AUTOSAR XML (schema 00047)
package /ETAS_FlatView/SwComponentTypes
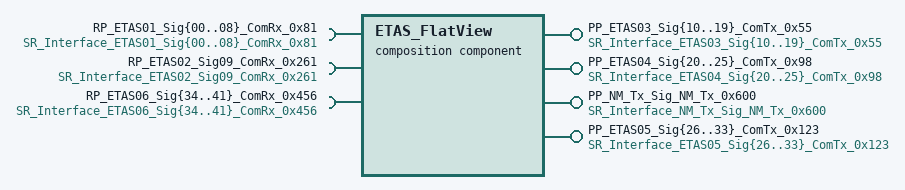
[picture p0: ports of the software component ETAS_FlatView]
  composition sw component type ETAS_FlatView
    17 x provide port:
      PP_ETAS03_Sig{10..19}_ComTx_0x55: provided-interface=SR_Interface_ETAS03_Sig{10..19}_ComTx_0x55
      PP_ETAS04_Sig{20..25}_ComTx_0x98: provided-interface=SR_Interface_ETAS04_Sig{20..25}_ComTx_0x98
      PP_NM_Tx_Sig_NM_Tx_0x600: provided-interface=SR_Interface_NM_Tx_Sig_NM_Tx_0x600
    10 x require port:
      RP_ETAS01_Sig{00..08}_ComRx_0x81: required-interface=SR_Interface_ETAS01_Sig{00..08}_ComRx_0x81
      RP_ETAS02_Sig09_ComRx_0x261: required-interface=SR_Interface_ETAS02_Sig09_ComRx_0x261
    8 x provide port:
      PP_ETAS05_Sig{26..33}_ComTx_0x123: provided-interface=SR_Interface_ETAS05_Sig{26..33}_ComTx_0x123
    8 x require port:
      RP_ETAS06_Sig{34..41}_ComRx_0x456: required-interface=SR_Interface_ETAS06_Sig{34..41}_ComRx_0x456
    23 x component:
      CPT_BswM: type=BswM
      CPT_CalUT: type=CalUT
      CPT_ComM: type=ComM
      CPT_Dcm: type=Dcm
      CPT_Dem: type=Dem
      CPT_Det: type=Det
      CPT_DiagUT: type=DiagUT
      CPT_EcuM: type=EcuM
      CPT_ExeMgrUT: type=ExeMgrUT
      CPT_FiM: type=FiM
      CPT_INP_SWC: type=INP_SWC
      CPT_NmUT: type=NmUT
      CPT_NvBlock: type=NvBlock
      CPT_NvM: type=NvM
      CPT_NvMUT: type=NvMUT
      CPT_OUTP_SWC: type=OUTP_SWC
      CPT_ParameterSWC: type=ParameterSWC
      CPT_Rtm: type=Rtm
      CPT_StackM: type=StackM
      CPT_TstM: type=TstM
      CPT_WdgM: type=WdgM
      CPT_WdgMUT: type=WdgMUT
      CPT_rba_DiagLib: type=rba_DiagLib
    connect CPT_ComM.UR_ComMUser_Can_Network_ETAS_Channel_Can_Network_ETAS -> CPT_NmUT.UR_ComMUser_Can_Network_ETAS_Channel
    connect CPT_ComM.modeLimitation -> CPT_NmUT.modeLimitation
    connect CPT_Dcm.DCMServices -> CPT_DiagUT.DCMServices
    connect CPT_Dcm.IOControlRequest_DID_0xD901_New_Data_Object -> CPT_DiagUT.IOControlRequest_DID_0xD901_New_Data_Object
    connect CPT_Dcm.IOControlRequest_DID_0xE900_New_Data_Object -> CPT_DiagUT.IOControlRequest_DID_0xE900_New_Data_Object
    connect CPT_Dcm.P_DataServices_DID_0x0100_New_Data_Object -> CPT_DiagUT.R_DataServices_DID_0x0100_New_Data_Object
    connect CPT_Dcm.P_DataServices_DID_0xF110_New_Data_Object -> CPT_DiagUT.R_DataServices_DID_0xF110_New_Data_Object
    connect CPT_Dcm.P_DataServices_DID_0xF115_New_Data_Object -> CPT_DiagUT.R_DataServices_DID_0xF115_New_Data_Object
    connect CPT_Dcm.P_DataServices_DID_0xF121_New_Data_Object -> CPT_DiagUT.R_DataServices_DID_0xF121_New_Data_Object
    connect CPT_Dcm.P_DataServices_DID_0xF187_New_Data_Object -> CPT_DiagUT.R_DataServices_DID_0xF187_New_Data_Object
    connect CPT_Dcm.P_DataServices_DID_0xF18B_New_Data_Object -> CPT_DiagUT.R_DataServices_DID_0xF18B_New_Data_Object
    connect CPT_Dcm.P_DataServices_DID_0xF18C_New_Data_Object -> CPT_DiagUT.R_DataServices_DID_0xF18C_New_Data_Object
    connect CPT_Dcm.P_DataServices_DID_0xF190_New_Data_Object -> CPT_DiagUT.R_DataServices_DID_0xF190_New_Data_Object
    connect CPT_Dcm.P_DataServices_DID_0xF198_New_Data_Object -> CPT_DiagUT.R_DataServices_DID_0xF198_New_Data_Object
    connect CPT_Dcm.P_DataServices_DID_0xF198_New_Data_Object_5 -> CPT_DiagUT.R_DataServices_DID_0xF198_New_Data_Object_5
    connect CPT_Dcm.P_DataServices_DID_0xF1A8_New_Data_Object -> CPT_DiagUT.R_DataServices_DID_0xF1A8_New_Data_Object
    connect CPT_Dcm.P_DataServices_DID_0xF1A9_New_Data_Object -> CPT_DiagUT.R_DataServices_DID_0xF1A9_New_Data_Object
    connect CPT_Dcm.P_DataServices_DID_0xF1AA_New_Data_Object -> CPT_DiagUT.R_DataServices_DID_0xF1AA_New_Data_Object
    connect CPT_Dcm.Pp_DcmCommunicationControl_Can_Network_ETAS_Channel_Can_Network_ETAS -> CPT_DiagUT.RR_DcmCommunicationControl_ComMChannel_Can_Network_ETAS_Channel
    connect CPT_Dcm.Pp_DcmControlDTCSetting -> CPT_DiagUT.RR_DcmControlDTCSetting
    connect CPT_Dcm.Pp_DcmDiagnosticSessionControl -> CPT_DiagUT.RR_DcmDiagnosticSessionControl
    connect CPT_Dcm.Pp_DcmEcuReset -> CPT_DiagUT.RR_DcmEcuReset
    connect CPT_Dem.ControlEventAvailable_DTC_0x000001_Event -> CPT_DiagUT.ControlEventAvailable_EventParameter_DTC_0x000001_Event
    connect CPT_Dem.ControlEventAvailable_DTC_0xc07388_Event -> CPT_DiagUT.ControlEventAvailable_EventParameter_DTC_0xc07388_Event
    connect CPT_Dem.ControlEventAvailable_DTC_0xc12687_Event -> CPT_DiagUT.ControlEventAvailable_EventParameter_DTC_0xc12687_Event
    connect CPT_Dem.ControlEventAvailable_DTC_0xc14587_Event -> CPT_DiagUT.ControlEventAvailable_EventParameter_DTC_0xc14587_Event
    connect CPT_Dem.ControlEventAvailable_DTC_0xc22a87_Event -> CPT_DiagUT.ControlEventAvailable_EventParameter_DTC_0xc22a87_Event
    connect CPT_Dem.ControlEventAvailable_DTC_0xc41487_Event -> CPT_DiagUT.ControlEventAvailable_EventParameter_DTC_0xc41487_Event
    connect CPT_Dem.ControlEventAvailable_DTC_0xd56217_Event -> CPT_DiagUT.ControlEventAvailable_EventParameter_DTC_0xd56217_Event
    connect CPT_Dem.ControlEventAvailable_DTC_0xd56316_Event -> CPT_DiagUT.ControlEventAvailable_EventParameter_DTC_0xd56316_Event
    connect CPT_Dem.ControlEventAvailable_DTC_0xe00141_Event -> CPT_DiagUT.ControlEventAvailable_EventParameter_DTC_0xe00141_Event
    connect CPT_Dem.ControlEventAvailable_DTC_0xe00142_Event -> CPT_DiagUT.ControlEventAvailable_EventParameter_DTC_0xe00142_Event
    connect CPT_Dem.ControlEventAvailable_DTC_0xe26200_Event -> CPT_DiagUT.ControlEventAvailable_EventParameter_DTC_0xe26200_Event
    connect CPT_Dem.EventStatus_DTC_0x000001_Event -> CPT_DiagUT.EventStatus_EventParameter_DTC_0x000001_Event
    connect CPT_Dem.EventStatus_DTC_0xc07388_Event -> CPT_DiagUT.EventStatus_EventParameter_DTC_0xc07388_Event
    connect CPT_Dem.EventStatus_DTC_0xc12687_Event -> CPT_DiagUT.EventStatus_EventParameter_DTC_0xc12687_Event
    connect CPT_Dem.EventStatus_DTC_0xc14587_Event -> CPT_DiagUT.EventStatus_EventParameter_DTC_0xc14587_Event
    connect CPT_Dem.EventStatus_DTC_0xc22a87_Event -> CPT_DiagUT.EventStatus_EventParameter_DTC_0xc22a87_Event
    connect CPT_Dem.EventStatus_DTC_0xc41487_Event -> CPT_DiagUT.EventStatus_EventParameter_DTC_0xc41487_Event
    connect CPT_Dem.EventStatus_DTC_0xd56217_Event -> CPT_DiagUT.EventStatus_EventParameter_DTC_0xd56217_Event
    connect CPT_Dem.EventStatus_DTC_0xd56316_Event -> CPT_DiagUT.EventStatus_EventParameter_DTC_0xd56316_Event
    connect CPT_Dem.EventStatus_DTC_0xe00141_Event -> CPT_DiagUT.EventStatus_EventParameter_DTC_0xe00141_Event
    connect CPT_Dem.EventStatus_DTC_0xe00142_Event -> CPT_DiagUT.EventStatus_EventParameter_DTC_0xe00142_Event
    connect CPT_Dem.EventStatus_DTC_0xe26200_Event -> CPT_DiagUT.EventStatus_EventParameter_DTC_0xe26200_Event
    connect CPT_Dem.Event_DTC_0x000001_Event -> CPT_DiagUT.Event_EventParameter_DTC_0x000001_Event
    connect CPT_Dem.Event_DTC_0xc07388_Event -> CPT_DiagUT.Event_EventParameter_DTC_0xc07388_Event
    connect CPT_Dem.Event_DTC_0xc12687_Event -> CPT_DiagUT.Event_EventParameter_DTC_0xc12687_Event
    connect CPT_Dem.Event_DTC_0xc14587_Event -> CPT_DiagUT.Event_EventParameter_DTC_0xc14587_Event
    connect CPT_Dem.Event_DTC_0xc22a87_Event -> CPT_DiagUT.Event_EventParameter_DTC_0xc22a87_Event
    connect CPT_Dem.Event_DTC_0xc41487_Event -> CPT_DiagUT.Event_EventParameter_DTC_0xc41487_Event
    connect CPT_Dem.Event_DTC_0xd56217_Event -> CPT_DiagUT.Event_EventParameter_DTC_0xd56217_Event
    connect CPT_Dem.Event_DTC_0xd56316_Event -> CPT_DiagUT.Event_EventParameter_DTC_0xd56316_Event
    connect CPT_Dem.Event_DTC_0xe00141_Event -> CPT_DiagUT.Event_EventParameter_DTC_0xe00141_Event
    connect CPT_Dem.Event_DTC_0xe00142_Event -> CPT_DiagUT.Event_EventParameter_DTC_0xe00142_Event
    connect CPT_Dem.Event_DTC_0xe26200_Event -> CPT_DiagUT.Event_EventParameter_DTC_0xe26200_Event
    connect CPT_Dem.EvtInfo_DTC_0x000001_Event -> CPT_DiagUT.EvtInfo_EventParameter_DTC_0x000001_Event
    connect CPT_Dem.EvtInfo_DTC_0x0d0400_CAN_Network_ETAS_BusOff_Event -> CPT_DiagUT.EvtInfo_EventParameter_DTC_0x0d0400_CAN_Network_ETAS_BusOff_Event
    connect CPT_Dem.EvtInfo_DTC_0xc07388_Event -> CPT_DiagUT.EvtInfo_EventParameter_DTC_0xc07388_Event
    connect CPT_Dem.EvtInfo_DTC_0xc12687_Event -> CPT_DiagUT.EvtInfo_EventParameter_DTC_0xc12687_Event
    connect CPT_Dem.EvtInfo_DTC_0xc14587_Event -> CPT_DiagUT.EvtInfo_EventParameter_DTC_0xc14587_Event
    connect CPT_Dem.EvtInfo_DTC_0xc22a87_Event -> CPT_DiagUT.EvtInfo_EventParameter_DTC_0xc22a87_Event
    connect CPT_Dem.EvtInfo_DTC_0xc41487_Event -> CPT_DiagUT.EvtInfo_EventParameter_DTC_0xc41487_Event
    connect CPT_Dem.EvtInfo_DTC_0xd56217_Event -> CPT_DiagUT.EvtInfo_EventParameter_DTC_0xd56217_Event
    connect CPT_Dem.EvtInfo_DTC_0xd56316_Event -> CPT_DiagUT.EvtInfo_EventParameter_DTC_0xd56316_Event
    connect CPT_Dem.EvtInfo_DTC_0xe00141_Event -> CPT_DiagUT.EvtInfo_EventParameter_DTC_0xe00141_Event
    connect CPT_Dem.EvtInfo_DTC_0xe00142_Event -> CPT_DiagUT.EvtInfo_EventParameter_DTC_0xe00142_Event
    connect CPT_Dem.EvtInfo_DTC_0xe26200_Event -> CPT_DiagUT.EvtInfo_EventParameter_DTC_0xe26200_Event
    connect CPT_Dem.GeneralEvtInfo -> CPT_DiagUT.GeneralEvtInfo
    connect CPT_Dem.OpCycle_DemOpCycle_DEM_POWER -> CPT_DiagUT.OpCycle_DemOpCycle_DEM_POWER
    connect CPT_Dem.StorageCond_DemStorageCondition -> CPT_DiagUT.StorageCond_DemStorageCondition_0
    connect CPT_DiagUT.CBClrEvt_EventParameter_DTC_0x000001_Event -> CPT_Dem.CBClrEvt_DTC_0x000001_Event
    connect CPT_DiagUT.CBClrEvt_EventParameter_DTC_0x0d0400_CAN_Network_ETAS_BusOff_Event -> CPT_Dem.CBClrEvt_DTC_0x0d0400_CAN_Network_ETAS_BusOff_Event
    connect CPT_DiagUT.CBClrEvt_EventParameter_DTC_0xc07388_Event -> CPT_Dem.CBClrEvt_DTC_0xc07388_Event
    connect CPT_DiagUT.CBClrEvt_EventParameter_DTC_0xc12687_Event -> CPT_Dem.CBClrEvt_DTC_0xc12687_Event
    connect CPT_DiagUT.CBClrEvt_EventParameter_DTC_0xc14587_Event -> CPT_Dem.CBClrEvt_DTC_0xc14587_Event
    connect CPT_DiagUT.CBClrEvt_EventParameter_DTC_0xc22a87_Event -> CPT_Dem.CBClrEvt_DTC_0xc22a87_Event
    connect CPT_DiagUT.CBClrEvt_EventParameter_DTC_0xc41487_Event -> CPT_Dem.CBClrEvt_DTC_0xc41487_Event
    connect CPT_DiagUT.CBClrEvt_EventParameter_DTC_0xd56217_Event -> CPT_Dem.CBClrEvt_DTC_0xd56217_Event
    connect CPT_DiagUT.CBClrEvt_EventParameter_DTC_0xd56316_Event -> CPT_Dem.CBClrEvt_DTC_0xd56316_Event
    connect CPT_DiagUT.CBClrEvt_EventParameter_DTC_0xe00141_Event -> CPT_Dem.CBClrEvt_DTC_0xe00141_Event
    connect CPT_DiagUT.CBClrEvt_EventParameter_DTC_0xe00142_Event -> CPT_Dem.CBClrEvt_DTC_0xe00142_Event
    connect CPT_DiagUT.CBClrEvt_EventParameter_DTC_0xe26200_Event -> CPT_Dem.CBClrEvt_DTC_0xe26200_Event
    connect CPT_DiagUT.IOControlResponse_DID_0xD901_New_Data_Object -> CPT_Dcm.IOControlResponse_DID_0xD901_New_Data_Object
    connect CPT_DiagUT.IOControlResponse_DID_0xE900_New_Data_Object -> CPT_Dcm.IOControlResponse_DID_0xE900_New_Data_Object
    connect CPT_DiagUT.P_DataServices_DID_0x0100_New_Data_Object -> CPT_Dcm.R_DataServices_DID_0x0100_New_Data_Object
    connect CPT_DiagUT.P_DataServices_DID_0x010B_Day -> CPT_Dcm.R_DataServices_DID_0x010B_Day
    connect CPT_DiagUT.P_DataServices_DID_0x010B_Hour -> CPT_Dcm.R_DataServices_DID_0x010B_Hour
    connect CPT_DiagUT.P_DataServices_DID_0x010B_Minute -> CPT_Dcm.R_DataServices_DID_0x010B_Minute
    connect CPT_DiagUT.P_DataServices_DID_0x010B_Month -> CPT_Dcm.R_DataServices_DID_0x010B_Month
    connect CPT_DiagUT.P_DataServices_DID_0x010B_Second -> CPT_Dcm.R_DataServices_DID_0x010B_Second
    connect CPT_DiagUT.P_DataServices_DID_0x010B_Year -> CPT_Dcm.R_DataServices_DID_0x010B_Year
    connect CPT_DiagUT.P_DataServices_DID_0x0112_New_Data_Object -> CPT_Dcm.R_DataServices_DID_0x0112_New_Data_Object
    connect CPT_DiagUT.P_DataServices_DID_0xB950_New_Data_Object -> CPT_Dcm.R_DataServices_DID_0xB950_New_Data_Object
    connect CPT_DiagUT.P_DataServices_DID_0xD001_New_Data_Object -> CPT_Dcm.R_DataServices_DID_0xD001_New_Data_Object
    connect CPT_DiagUT.P_DataServices_DID_0xD901_New_Data_Object -> CPT_Dcm.R_DataServices_DID_0xD901_New_Data_Object
    connect CPT_DiagUT.P_DataServices_DID_0xE101_New_Data_Object -> CPT_Dcm.R_DataServices_DID_0xE101_New_Data_Object
    connect CPT_DiagUT.P_DataServices_DID_0xE900_New_Data_Object -> CPT_Dcm.R_DataServices_DID_0xE900_New_Data_Object
    connect CPT_DiagUT.P_DataServices_DID_0xF100_New_Data_Object -> CPT_Dcm.R_DataServices_DID_0xF100_New_Data_Object
    connect CPT_DiagUT.P_DataServices_DID_0xF100_New_Data_Object_1 -> CPT_Dcm.R_DataServices_DID_0xF100_New_Data_Object_1
    connect CPT_DiagUT.P_DataServices_DID_0xF{110..119}_New_Data_Object -> CPT_Dcm.R_DataServices_DID_0xF{110..119}_New_Data_Object
    connect CPT_DiagUT.P_DataServices_DID_0xF11A_New_Data_Object -> CPT_Dcm.R_DataServices_DID_0xF11A_New_Data_Object
    connect CPT_DiagUT.P_DataServices_DID_0xF11B_New_Data_Object -> CPT_Dcm.R_DataServices_DID_0xF11B_New_Data_Object
    connect CPT_DiagUT.P_DataServices_DID_0xF11C_New_Data_Object -> CPT_Dcm.R_DataServices_DID_0xF11C_New_Data_Object
    connect CPT_DiagUT.P_DataServices_DID_0xF11D_New_Data_Object -> CPT_Dcm.R_DataServices_DID_0xF11D_New_Data_Object
    connect CPT_DiagUT.P_DataServices_DID_0xF11E_New_Data_Object -> CPT_Dcm.R_DataServices_DID_0xF11E_New_Data_Object
    connect CPT_DiagUT.P_DataServices_DID_0xF11F_New_Data_Object -> CPT_Dcm.R_DataServices_DID_0xF11F_New_Data_Object
    connect CPT_DiagUT.P_DataServices_DID_0xF{120..122}_New_Data_Object -> CPT_Dcm.R_DataServices_DID_0xF{120..122}_New_Data_Object
    connect CPT_DiagUT.P_DataServices_DID_0xF122_New_Data_Object_2 -> CPT_Dcm.R_DataServices_DID_0xF122_New_Data_Object_2
    connect CPT_DiagUT.P_DataServices_DID_0xF187_New_Data_Object -> CPT_Dcm.R_DataServices_DID_0xF187_New_Data_Object
    connect CPT_DiagUT.P_DataServices_DID_0xF18A_New_Data_Object -> CPT_Dcm.R_DataServices_DID_0xF18A_New_Data_Object
    connect CPT_DiagUT.P_DataServices_DID_0xF18B_New_Data_Object -> CPT_Dcm.R_DataServices_DID_0xF18B_New_Data_Object
    connect CPT_DiagUT.P_DataServices_DID_0xF18C_New_Data_Object -> CPT_Dcm.R_DataServices_DID_0xF18C_New_Data_Object
    connect CPT_DiagUT.P_DataServices_DID_0xF190_New_Data_Object -> CPT_Dcm.R_DataServices_DID_0xF190_New_Data_Object
    connect CPT_DiagUT.P_DataServices_DID_0xF192_New_Data_Object -> CPT_Dcm.R_DataServices_DID_0xF192_New_Data_Object
    connect CPT_DiagUT.P_DataServices_DID_0xF192_New_Data_Object_3 -> CPT_Dcm.R_DataServices_DID_0xF192_New_Data_Object_3
    connect CPT_DiagUT.P_DataServices_DID_0xF194_New_Data_Object -> CPT_Dcm.R_DataServices_DID_0xF194_New_Data_Object
    connect CPT_DiagUT.P_DataServices_DID_0xF194_New_Data_Object_4 -> CPT_Dcm.R_DataServices_DID_0xF194_New_Data_Object_4
    connect CPT_DiagUT.P_DataServices_DID_0xF198_New_Data_Object -> CPT_Dcm.R_DataServices_DID_0xF198_New_Data_Object
    connect CPT_DiagUT.P_DataServices_DID_0xF198_New_Data_Object_5 -> CPT_Dcm.R_DataServices_DID_0xF198_New_Data_Object_5
    connect CPT_DiagUT.P_DataServices_DID_0xF1A{0..2}_New_Data_Object -> CPT_Dcm.R_DataServices_DID_0xF1A{0..2}_New_Data_Object
    connect CPT_DiagUT.P_DataServices_DID_0xF1A5_New_Data_Object -> CPT_Dcm.R_DataServices_DID_0xF1A5_New_Data_Object
    connect CPT_DiagUT.P_DataServices_DID_0xF1A8_New_Data_Object -> CPT_Dcm.R_DataServices_DID_0xF1A8_New_Data_Object
    connect CPT_DiagUT.P_DataServices_DID_0xF1A9_New_Data_Object -> CPT_Dcm.R_DataServices_DID_0xF1A9_New_Data_Object
    connect CPT_DiagUT.P_DataServices_DID_0xF1AA_New_Data_Object -> CPT_Dcm.R_DataServices_DID_0xF1AA_New_Data_Object
    connect CPT_DiagUT.RoutineServices_DcmDspRoutine_Routine_Control_203 -> CPT_Dcm.RoutineServices_Routine_Control_203
    connect CPT_DiagUT.RoutineServices_DcmDspRoutine_Routine_Control_ABFF -> CPT_Dcm.RoutineServices_Routine_Control_ABFF
    connect CPT_DiagUT.RoutineServices_DcmDspRoutine_X_Routine_Control_ABFE -> CPT_Dcm.RoutineServices_X_Routine_Control_ABFE
    connect CPT_DiagUT.SecurityAccess_UnlockedL1 -> CPT_Dcm.SecurityAccess_UnlockedL1
    connect CPT_DiagUT.SecurityAccess_Unlocked_L3 -> CPT_Dcm.SecurityAccess_Unlocked_L3
    connect CPT_EcuM.shutdownTarget -> CPT_ExeMgrUT.RP_EcuM_SelectResetTarget
    connect CPT_ExeMgrUT.PP_BswM_APPMode -> CPT_BswM.RP_BswM_MRP_SWC_AppMode
    connect CPT_ExeMgrUT.PP_RequestReset -> CPT_NvMUT.RP_RequestReset
    connect CPT_ExeMgrUT.PP_ResetInfo -> CPT_NvMUT.RP_ResetInfo
    connect CPT_NvBlock.PRP_StoreAtShutdownBlock -> CPT_NvMUT.PRP_ShutdownNvBlock
    connect CPT_NvBlock.PRP_StoreCyclicBlock -> CPT_NvMUT.PRP_CyclicNvBlock
    connect CPT_NvBlock.PRP_StoreImmediateBlock -> CPT_NvMUT.PRP_ImmediateNvBlock
    connect CPT_NvMUT.PP_CyclicBlock_JobFinished -> CPT_NvBlock.RP_StoreCyclicBlock
    connect CPT_NvMUT.PP_ImmediateBlock_JobFinished -> CPT_NvBlock.RP_StoreImmediateBlock
    connect CPT_NvMUT.PP_ShutdownBlock_JobFinished -> CPT_NvBlock.RP_StoreAtShutdownBlock
    connect CPT_ParameterSWC.PP_SpeedLimit -> CPT_CalUT.RP_SpeedLimit
    connect CPT_StackM.GetStackInfo -> CPT_TstM.GetStackInfo
    connect CPT_WdgM.globalMode -> CPT_WdgMUT.RP_WdgM_GlobalMode
    connect CPT_WdgM.globalSupervision -> CPT_WdgMUT.RP_WdgM_GlobalSupervision
    connect CPT_WdgM.localSupervisionStatus_WdgM_SE1 -> CPT_WdgMUT.RP_WdgM_LocalSupervisionStatus
    connect CPT_WdgM.localSupervision_WdgM_SE1_WdgM_SE1_Alive_CP -> CPT_WdgMUT.RP_AliveSupervision_ASW_10ms
    connect CPT_WdgM.localSupervision_WdgM_SE1_WdgM_SE1_Deadline_CP_0 -> CPT_WdgMUT.RP_Deadline_Start_ASW_10ms
    connect CPT_WdgM.localSupervision_WdgM_SE1_WdgM_SE1_Deadline_CP_1 -> CPT_WdgMUT.RP_Deadline_Stop_ASW_10ms
    connect CPT_WdgM.localSupervision_WdgM_SE1_WdgM_SE1_PFM_CP_0 -> CPT_WdgMUT.RP_PFM_CP0_ASW_10ms
    connect CPT_WdgM.localSupervision_WdgM_SE1_WdgM_SE1_PFM_CP_1 -> CPT_WdgMUT.RP_PFM_CP1_ASW_10ms
    connect CPT_WdgM.mode_WdgM_SE1 -> CPT_WdgMUT.RP_WdgM_WdgM_SE1_Mode
    delegate CPT_NmUT.PP_NM_Tx_Sig_NM_Tx_0x600 <-> outer port PP_NM_Tx_Sig_NM_Tx_0x600
    delegate CPT_OUTP_SWC.PP_ETAS03_Sig{10..19}_ComTx_0x55 <-> outer port PP_ETAS03_Sig{10..19}_ComTx_0x55
    delegate CPT_OUTP_SWC.PP_ETAS04_Sig{20..25}_ComTx_0x98 <-> outer port PP_ETAS04_Sig{20..25}_ComTx_0x98
    delegate CPT_INP_SWC.RP_ETAS01_Sig{00..08}_ComRx_0x81 <-> outer port RP_ETAS01_Sig{00..08}_ComRx_0x81
    delegate CPT_INP_SWC.RP_ETAS02_Sig09_ComRx_0x261 <-> outer port RP_ETAS02_Sig09_ComRx_0x261
    delegate CPT_OUTP_SWC.PP_ETAS05_Sig{26..33}_ComTx_0x123 <-> outer port PP_ETAS05_Sig{26..33}_ComTx_0x123
    delegate CPT_INP_SWC.RP_ETAS06_Sig{34..41}_ComRx_0x456 <-> outer port RP_ETAS06_Sig{34..41}_ComRx_0x456
